# CKMD register map
Vendor: Texas Instruments
Registers are 32-bit, access per field, reset 0x0 unless marked. A register's access mark holds for its fields unless they carry their own. Offsets are as the file gives them; [hi:lo] are bit positions; 'fields as' and 'values as' point back to an identical list.

## CKMD (part 2 of 2) — Clock Controller
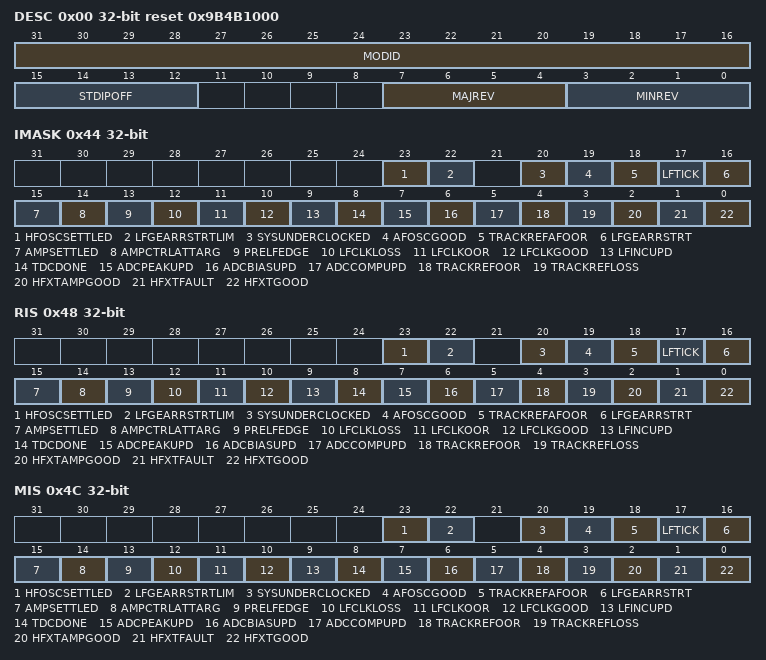
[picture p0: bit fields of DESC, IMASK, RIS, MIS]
0x00 DESC ro reset 0x9B4B1000 — IP Description
  [31:16] MODID — Module identifier
  [15:12] STDIPOFF — Standard IP MMR block offset
  [7:4] MAJREV — Major revision
  [3:0] MINREV — Minor revision
0x44 IMASK — Interrupt mask. This register selects interrupt sources which are allowed to pass from RIS to MIS when the corresponding bit-fields are set to 1.
  [23] HFOSCSETTLED rw — Indicates that HFOSC has settled, based on LOOPCFG.SETTLED_TARGET and LOOPCFG1.SETTLEIRQ
  [22] LFGEARRSTRTLIM rw — Indicates that the LFINC filter gearing mechanism has restarted more than LFINCCTL2.GEARRSTRTLIM
  [20] SYSUNDERCLOCKED rw — Indicates system frequency has been lowered. It will be set only if HFTRACKCTL.UNDERCLK is appropriately configured and HFOSC tracking loop is not running.
  [19] AFOSCGOOD rw — AFOSC good indication.
  [18] TRACKREFAFOOR rw — Out-of-range indication from the AFOSC tracking loop. Indicates that the reference clock frequency of AFOSC tracking loop is out-of-range.
  [17] LFTICK rw — 32kHz TICK to RTC and WDT. Either derived from selected LFCLK or generated from CLKULL in absence of LFCLK.
  [16] LFGEARRSTRT rw — LFINC filter gearing restart. Indicates that the LFINC filter restarted gearing. Subsequent LFINC estimates may have higher variation.
  [15] AMPSETTLED rw — HFXT Amplitude compensation - settled Indicates that the amplitude compensation FSM has reached the SETTLED or TCXOMODE state, and the controls configured in HFXTTARG or HFXTDYN are reached.
  [14] AMPCTRLATTARG rw — HFXT Amplitude compensation - controls at target Indicates that the control values configured in HFXTTARG or HFXTDYN are reached. Applies to Q1CAP, Q2CAP and IREF.
  [13] PRELFEDGE rw — Pre-LF clock edge detect. Indicates that a positive edge occured on the selected pre-LF clock CLKSEL.PRELFCLK' Can be used by software to confirm that a LF clock source is running and within the expected frequency, before selecting it as the main LF clock source.
  [12] LFCLKLOSS rw — LF clock is lost. Indicates that no LF clock edge occured for ~49us (~1.6 times nominal period). The system will automatically fall-back to generating LFTICK based on CLKULL, to avoid timing corruption. Note that this signal is NOT related to the analog LF clock-loss detector which can reset the device during STANDBY.
  [11] LFCLKOOR rw — LF clock period out-of-range. Indicates that a LF clock period was measured to be out-of-range, according to LFQUALCTL.MAXERR.
  [10] LFCLKGOOD rw — LF clock good. Indicates that the LF clock is good, according to the configuration in LFQUALCTL.
  [9] LFINCUPD rw — LFINC updated. Indicates that a new LFINC measurement value is available in LFCLKSTAT.LFINC.
  [8] TDCDONE rw — TDC done event. Indicates that the TDC measurement is done.
  [7] ADCPEAKUPD rw — HFXT-ADC PEAK measurement update event. Indicates that the HFXT-ADC PEAK measurement is done.
  [6] ADCBIASUPD rw — HFXT-ADC BIAS measurement update event. Indicates that the HFXT-ADC BIAS measurement is done.
  [5] ADCCOMPUPD rw — HFXT-ADC comparison update event. Indicates that the HFXT-ADC comparison is done.
  [4] TRACKREFOOR rw — Out-of-range indication from the tracking loop. Indicates that the selected reference clock frequency of the tracking loop is out-of-range.
  [3] TRACKREFLOSS rw — Clock loss indication from the tracking loop. Indicates that the selected reference clock of the tracking loop is lost.
  [2] HFXTAMPGOOD rw — HFXT amplitude good indication.
  [1] HFXTFAULT rw — HFXT fault indication. Indicates that HFXT did not start correctly, or its frequency is too low. HFXT will not recover from this fault and has to be restarted. This is only a one-time check at HFXT startup.
  [0] HFXTGOOD rw — HFXT good indication. Indicates that HFXT started correctly. The frequency is not necessarily good enough for radio operation. This is only a one-time check at HFXT startup.
0x48 RIS ro — Raw interrupt flag register
  [23] HFOSCSETTLED — Indicates that HFOSC has settled, based on LOOPCFG.SETTLED_TARGET and LOOPCFG1.SETTLEIRQ
  [22] LFGEARRSTRTLIM — Indicates that the LFINC filter gearing mechanism has restarted more than LFINCCTL2.GEARRSTRTLIM
  [20] SYSUNDERCLOCKED — Indicates system frequency has been lowered. It will be set only if HFTRACKCTL.UNDERCLK is appropriately configured and HFOSC tracking loop is not running.
  [19] AFOSCGOOD — AFOSC good indication.
  [18] TRACKREFAFOOR — Out-of-range indication from the AFOSC tracking loop. Indicates that the reference clock frequency of AFOSC tracking loop is out-of-range.
  [17] LFTICK — 32kHz TICK to RTC and WDT. Either derived from selected LFCLK or generated from CLKULL in absence of LFCLK.
  [16] LFGEARRSTRT — LFINC filter gearing restart. Indicates that the LFINC filter restarted gearing. Subsequent LFINC estimates may have higher variation.
  [15] AMPSETTLED — HFXT Amplitude compensation - settled Indicates that the amplitude compensation FSM has reached the SETTLED or TCXOMODE state, and the controls configured in HFXTTARG or HFXTDYN are reached.
  [14] AMPCTRLATTARG — HFXT Amplitude compensation - controls at target Indicates that the control values configured in HFXTTARG or HFXTDYN are reached. Applies to Q1CAP, Q2CAP and IREF.
  [13] PRELFEDGE — Pre-LF clock edge detect. Indicates that a positive edge occured on the selected pre-LF clock CLKSEL.PRELFCLK' Can be used by software to confirm that a LF clock source is running and within the expected frequency, before selecting it as the main LF clock source.
  [12] LFCLKLOSS — LF clock is lost. Indicates that no LF clock edge occured for ~49us (~1.6 times nominal period). The system will automatically fall-back to generating LFTICK based on CLKULL, to avoid timing corruption. Note that this signal is NOT related to the analog LF clock-loss detector which can reset the device during STANDBY.
  [11] LFCLKOOR — LF clock period out-of-range. Indicates that a LF clock period was measured to be out-of-range, according to LFQUALCTL.MAXERR.
  [10] LFCLKGOOD — LF clock good. Indicates that the LF clock is good, according to the configuration in LFQUALCTL.
  [9] LFINCUPD — LFINC updated. Indicates that a new LFINC measurement value is available in LFCLKSTAT.LFINC.
  [8] TDCDONE — TDC done event. Indicates that the TDC measurement is done.
  [7] ADCPEAKUPD — HFXT-ADC PEAK measurement update event. Indicates that the HFXT-ADC PEAK measurement is done.
  [6] ADCBIASUPD — HFXT-ADC BIAS measurement update event. Indicates that the HFXT-ADC BIAS measurement is done.
  [5] ADCCOMPUPD — HFXT-ADC comparison update event. Indicates that the HFXT-ADC comparison is done.
  [4] TRACKREFOOR — Out-of-range indication from the tracking loop. Indicates that the selected reference clock frequency of the tracking loop is out-of-range.
  [3] TRACKREFLOSS — Clock loss indication from the tracking loop. Indicates that the selected reference clock of the tracking loop is lost.
  [2] HFXTAMPGOOD — HFXT amplitude good indication.
  [1] HFXTFAULT — HFXT fault indication. Indicates that HFXT did not start correctly, or its frequency is too low. HFXT will not recover from this fault and has to be restarted. This is only a one-time check at HFXT startup.
  [0] HFXTGOOD — HFXT good indication. Indicates that HFXT started correctly. The frequency is not necessarily good enough for radio operation. This is only a one-time check at HFXT startup.
0x4C MIS ro — Masked interrupt flag register
  fields as RIS
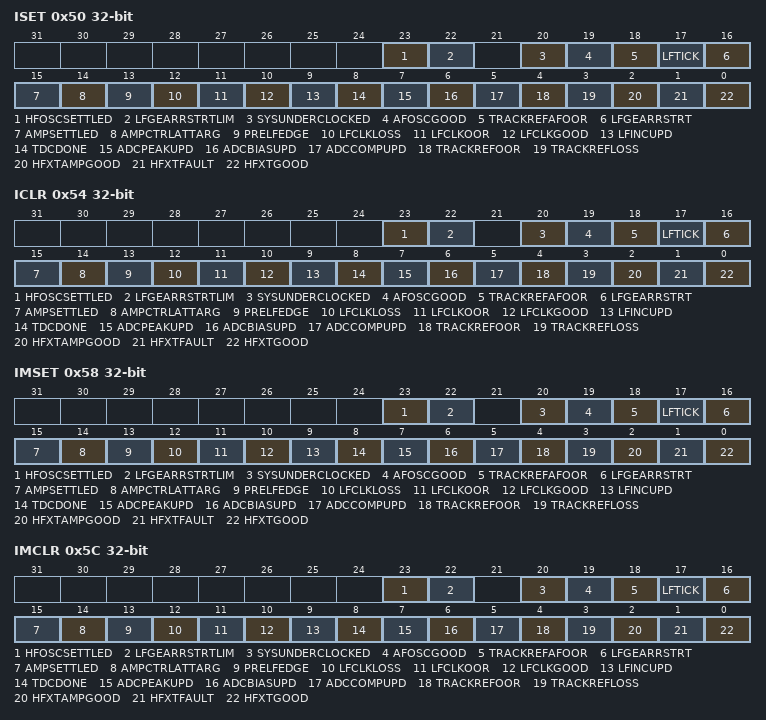
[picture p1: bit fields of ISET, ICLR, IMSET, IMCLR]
0x50 ISET — Interrupt flag set register
  [23] HFOSCSETTLED wo — Indicates that HFOSC has settled, based on LOOPCFG.SETTLED_TARGET and LOOPCFG1.SETTLEIRQ
  [22] LFGEARRSTRTLIM wo — Indicates that the LFINC filter gearing mechanism has restarted more than LFINCCTL2.GEARRSTRTLIM
  [20] SYSUNDERCLOCKED wo — Indicates system frequency has been lowered. It will be set only if HFTRACKCTL.UNDERCLK is appropriately configured and HFOSC tracking loop is not running.
  [19] AFOSCGOOD wo — AFOSC good indication.
  [18] TRACKREFAFOOR wo — Out-of-range indication from the AFOSC tracking loop. Indicates that the reference clock frequency of AFOSC tracking loop is out-of-range.
  [17] LFTICK wo — 32kHz TICK to RTC and WDT. Either derived from selected LFCLK or generated from CLKULL in absence of LFCLK.
  [16] LFGEARRSTRT wo — LFINC filter gearing restart. Indicates that the LFINC filter restarted gearing. Subsequent LFINC estimates may have higher variation.
  [15] AMPSETTLED wo — HFXT Amplitude compensation - settled Indicates that the amplitude compensation FSM has reached the SETTLED or TCXOMODE state, and the controls configured in HFXTTARG or HFXTDYN are reached.
  [14] AMPCTRLATTARG wo — HFXT Amplitude compensation - controls at target Indicates that the control values configured in HFXTTARG or HFXTDYN are reached. Applies to Q1CAP, Q2CAP and IREF.
  [13] PRELFEDGE wo — Pre-LF clock edge detect. Indicates that a positive edge occured on the selected pre-LF clock CLKSEL.PRELFCLK' Can be used by software to confirm that a LF clock source is running and within the expected frequency, before selecting it as the main LF clock source.
  [12] LFCLKLOSS wo — LF clock is lost. Indicates that no LF clock edge occured for ~49us (~1.6 times nominal period). The system will automatically fall-back to generating LFTICK based on CLKULL, to avoid timing corruption. Note that this signal is NOT related to the analog LF clock-loss detector which can reset the device during STANDBY.
  [11] LFCLKOOR wo — LF clock period out-of-range. Indicates that a LF clock period was measured to be out-of-range, according to LFQUALCTL.MAXERR.
  [10] LFCLKGOOD wo — LF clock good. Indicates that the LF clock is good, according to the configuration in LFQUALCTL.
  [9] LFINCUPD wo — LFINC updated. Indicates that a new LFINC measurement value is available in LFCLKSTAT.LFINC.
  [8] TDCDONE wo — TDC done event. Indicates that the TDC measurement is done.
  [7] ADCPEAKUPD wo — HFXT-ADC PEAK measurement update event. Indicates that the HFXT-ADC PEAK measurement is done.
  [6] ADCBIASUPD wo — HFXT-ADC BIAS measurement update event. Indicates that the HFXT-ADC BIAS measurement is done.
  [5] ADCCOMPUPD wo — HFXT-ADC comparison update event. Indicates that the HFXT-ADC comparison is done.
  [4] TRACKREFOOR wo — Out-of-range indication from the tracking loop. Indicates that the selected reference clock frequency of the tracking loop is out-of-range.
  [3] TRACKREFLOSS wo — Clock loss indication from the tracking loop. Indicates that the selected reference clock of the tracking loop is lost.
  [2] HFXTAMPGOOD wo — HFXT amplitude good indication.
  [1] HFXTFAULT wo — HFXT fault indication. Indicates that HFXT did not start correctly, or its frequency is too low. HFXT will not recover from this fault and has to be restarted. This is only a one-time check at HFXT startup.
  [0] HFXTGOOD wo — HFXT good indication. Indicates that HFXT started correctly. The frequency is not necessarily good enough for radio operation. This is only a one-time check at HFXT startup.
0x54 ICLR — Interrupt flag clear register
  fields as ISET
0x58 IMSET — Interrupt mask set register
  fields as ISET
0x5C IMCLR — Interrupt mask clear register. Writing a 1 to a bit in this register will clear the corresponding IMASK bit.
  fields as ISET
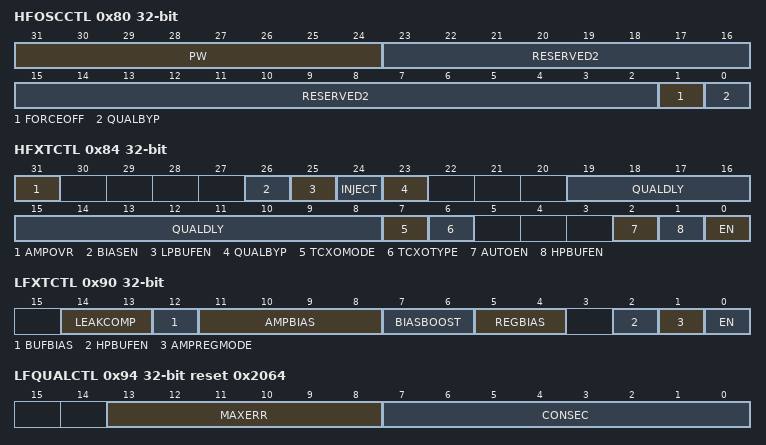
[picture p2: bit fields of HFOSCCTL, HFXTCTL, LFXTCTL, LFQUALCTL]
0x80 HFOSCCTL — Internal. Only to be used through TI provided API.
  [31:24] PW wo — Internal. Only to be used through TI provided API.
  [23:2] RESERVED2 ro — Internal. Only to be used through TI provided API.
  [1] FORCEOFF rw — Internal. Only to be used through TI provided API.
  [0] QUALBYP rw — Internal. Only to be used through TI provided API.
0x84 HFXTCTL — High frequency crystal control
  [31] AMPOVR rw — Internal. Only to be used through TI provided API.
  [26] BIASEN rw — Internal. Only to be used through TI provided API.
  [25] LPBUFEN rw — Internal. Only to be used through TI provided API.
  [24] INJECT rw — Internal. Only to be used through TI provided API.
  [23] QUALBYP rw — Internal. Only to be used through TI provided API.
  [19:8] QUALDLY rw — Skip potentially unstable clock cycles after enabling HFXT. Number of cycles skipped is 8*QUALDLY.
  [7] TCXOMODE rw — Temperature compensated crystal oscillator mode. Set this bit if a TXCO is connected.
  [6] TCXOTYPE rw — Type of temperature compensated crystal used. Only has effect if TCXOMODE is set.
    1=CMOS (Use with CMOS TCXO); 0=CLIPPEDSINE (Use with clipped-sine TCXO)
  [2] AUTOEN rw — Internal. Only to be used through TI provided API.
  [1] HPBUFEN rw — High performance clock buffer enable. This bit controls the clock output for the RF PLL. It is required for radio operation.
  [0] EN rw — Internal. Only to be used through TI provided API.
0x8C LFOSCCTL — Low frequency oscillator control
  [0] EN rw — LFOSC enable
0x90 LFXTCTL — Low frequency crystal control
  [14:13] LEAKCOMP rw — Leakage compensation control
    3=OFF (No leakage compensation); 1=HALF (Half leakage compensation); 0=FULL (Full leakage compensation)
  [12] BUFBIAS rw — Control the BIAS current of the input amp in LP buffer
    1=MAX (Maximum bias current: 50nA); 0=MIN (Minimum bias current: 25nA)
  [11:8] AMPBIAS rw — Adjust current mirror ratio into oscillator core. This value is depending on crystal and is set by FW. This field uses a 2's complement encoding.
  [7:6] BIASBOOST rw — Boost oscillator amplitude This value depends on the crystal and needs to be configured by Firmware.
  [5:4] REGBIAS rw — Regulation loop bias resistor value This value depends on the crystal and needs to be configured by Firmware.
  [2] HPBUFEN rw — Control the buffer used. In normal operation, low-power buffer is used in all device modes. The high-performance buffer is only used for test purposes.
  [1] AMPREGMODE rw — Amplitude regulation mode
    1=LOOPDIS (Amplitude control loop disabled); 0=LOOPEN (Amplitude control loop enabled)
  [0] EN rw — LFXT enable
0x94 LFQUALCTL reset 0x2064 — Low frequency clock qualification control
  [13:8] MAXERR rw — Maximum LFCLK period error. Value given in microseconds, 3 integer bits + 3 fractional bits.
  [7:0] CONSEC rw — Number of consecutive times the LFCLK period error has to be smaller than MAXERR to be considered "good". Setting this value to 0 will bypass clock qualification, and the "good" indicator will always be 1.
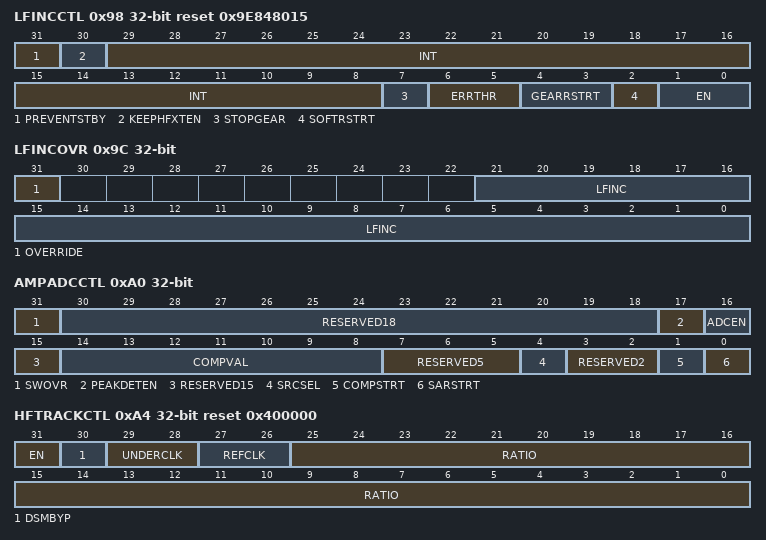
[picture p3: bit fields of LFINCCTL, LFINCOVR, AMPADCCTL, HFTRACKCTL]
0x98 LFINCCTL rw reset 0x9E848015 — Low frequency time increment control
  [31] PREVENTSTBY — Controls if the LFINC filter prevents STANBY entry until settled.
    1=ON (Enable. Prevent STANDBY entry.); 0=OFF (Disable. Do not prevent STANDBY entry.)
  [30] KEEPHFXTEN — Keeps the HFXT enabled till the LFINC filter settles
    1=EN (Enable. Keep HFXT enabled.); 0=DIS (Disable. Do not keep HFXT enabled.)
  [29:8] INT — Integral part of the LFINC filter. This value is updated by Hardware to reflect the current state of the filter. It can also be written to change the current state.
  [7] STOPGEAR — Controls the final gear of the LFINC filter.
    1=HIGH (The LF filter is considered settled when LFCLKSTAT2.MAINGEAR reads 8 and LFCLKSTAT2.SUBGEAR reads 7. That means the LF filter will take 71 LF periods to settle provided the gear does not restarts.); 0=LOW (The LF filter is considered settled when LFCLKSTAT2.MAINGEAR reads 9 and LFCLKSTAT2.SUBGEAR reads 7. That means the LF filter will take 79 LF periods to settle provided the gear does not restarts.)
  [6:5] ERRTHR — Controls the threshold for gearing restart of the LFINC filter. Only effective if GEARRSTRT is not ONETHR or TWOTHR.
    3=SMALL (Restart gearing on small error. Potentially more false restarts, faster response on small frequency shifts.); 2=MIDSMALL (Middle value towards SMALL.); 1=MIDLARGE (Middle value towards LARGE.); 0=LARGE (Restart gearing on large error. Fewer false restarts, slower response on small frequency shifts.)
  [4:3] GEARRSTRT — Controls gearing restart of the LFINC filter.
    2=TWOTHR (Restart gearing when the error accumulator crosses the threshold twice in a row.); 1=ONETHR (Restart gearing when the error accumulator crosses the threshold once.); 0=NEVER (Never restart gearing. Very stable filter value, but very slow response on frequency changes.)
  [2] SOFTRSTRT — Use a higher gear after re-enabling / wakeup. The filter will require 16-24 LFCLK periods to settle (depending on STOPGEAR), but may respond faster to frequency changes during STANDBY.
    1=ON (Use soft gearing restarts); 0=OFF (Don't use soft gearing restarts)
  [1:0] EN — Enable LFINC filter. Programming with a value of 0x3 will disable the LFINC filter
    2=AUTO (Enable based on HFOS getting settled. HFOSC gets settled after the tracking loop has updated equal to or more than LOOPCFG.SETTLED_TARGET times.); 1=EN (ENABLED); 0=DIS (DISABLED)
0x9C LFINCOVR — Low frequency time increment override control
  [31] OVERRIDE rw — Override LF increment Use the value provided in LFINC instead of the value calculated by Hardware.
  [21:0] LFINC rw — LF increment value This value is used when OVERRIDE is set to 1. Otherwise the value is calculated automatically. The current LFINC value can be read from [CKM.LFCLKSTAT.LFINC].
0xA0 AMPADCCTL — Internal. Only to be used through TI provided API.
  [31] SWOVR rw — Internal. Only to be used through TI provided API.
  [30:18] RESERVED18 ro — Internal. Only to be used through TI provided API.
  [17] PEAKDETEN rw — Internal. Only to be used through TI provided API.
    1=ENABLE (Internal. Only to be used through TI provided API.); 0=DISABLE (Internal. Only to be used through TI provided API.)
  [16] ADCEN rw — Internal. Only to be used through TI provided API.
    values as PEAKDETEN
  [15] RESERVED15 ro — Internal. Only to be used through TI provided API.
  [14:8] COMPVAL rw — Internal. Only to be used through TI provided API.
  [7:5] RESERVED5 ro — Internal. Only to be used through TI provided API.
  [4] SRCSEL rw — Internal. Only to be used through TI provided API.
    1=PEAK (Internal. Only to be used through TI provided API.); 0=BIAS (Internal. Only to be used through TI provided API.)
  [3:2] RESERVED2 ro — Internal. Only to be used through TI provided API.
  [1] COMPSTRT rw — Internal. Only to be used through TI provided API.
  [0] SARSTRT rw — Internal. Only to be used through TI provided API.
0xA4 HFTRACKCTL rw reset 0x400000 — High frequency tracking loop control
  [31] EN — Enable tracking loop.
  [30] DSMBYP — Bypass Delta-Sigma-Modulation of fine trim.
  [29:28] UNDERCLK — When the HFOSC tracking loop is not running, this bitfield can be used to set the condition to automatically lower the HFOSC frequency. This will prevent frequency drift that may lead to SOC instability.
    3=BOTH (Temperature event from Batmon or Timer event); 2=BATMON (Temperature event from Batmon); 1=TIMER (Timer event); 0=DIS (Disable)
  [27:26] REFCLK — Select the reference clock for the tracking loop. Change only while the tracking loop is disabled.
    2=GPI (Select GPI as reference clock.); 1=LRF (Select LRF reference clock.); 0=HFXT (Select HFXT as reference clock.)
  [25:0] RATIO — Reference clock ratio. Ratio format is 2b.24b RATIO = 24MHz / (2*reference-frequency) * 2^24 Commonly used reference clock frequencies are provided as enumerations.
    0x3000000=REF4M (Use for 4MHz reference clock); 0x1800000=REF8M (Use for 8MHz Reference clock); 0x400000=REF48M (Use for 48MHz reference clock)
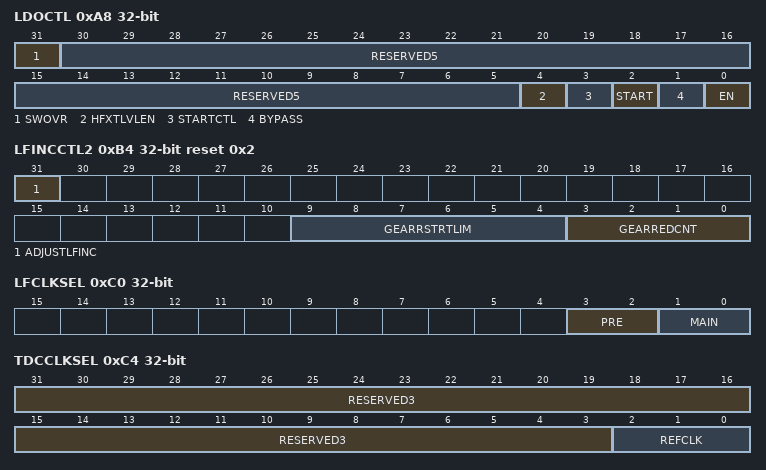
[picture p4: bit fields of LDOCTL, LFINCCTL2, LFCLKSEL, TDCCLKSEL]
0xA8 LDOCTL — Internal. Only to be used through TI provided API.
  [31] SWOVR rw — Internal. Only to be used through TI provided API.
  [30:5] RESERVED5 ro — Internal. Only to be used through TI provided API.
  [4] HFXTLVLEN rw — Internal. Only to be used through TI provided API.
  [3] STARTCTL rw — Internal. Only to be used through TI provided API.
  [2] START rw — Internal. Only to be used through TI provided API.
  [1] BYPASS rw — Internal. Only to be used through TI provided API.
  [0] EN rw — Internal. Only to be used through TI provided API.
0xAC NABIASCTL — Nanoamp-bias control
  [0] EN rw — Enable nanoamp-bias
0xB0 LFMONCTL — Low-frequency clock-monitor control
  [0] EN rw — Enable LFMONITOR. Enable only after a LF clock source has been selected, enabled and is stable. If LFMONITOR detects a clock loss, the system will be reset.
0xB4 LFINCCTL2 reset 0x2 — Low frequency time increment control-2
  [31] ADJUSTLFINC rw — Adjusts LFINC while transitioning from fake to real LF clock if necessary. For the adjustment to happen, tracking loop must be running.
  [9:4] GEARRSTRTLIM rw — Specifies the number of times gear could be restarted before raising an interrupt. It has no impact on the number of times gear can be reduced. A value of 0 indicates that the interrupt mechanism is disabled
  [3:0] GEARREDCNT rw — Specifies the number by which gear should be reduced post standby exit
0xC0 LFCLKSEL — Low frequency clock selection
  [3:2] PRE rw — Select low frequency clock source for the PRELFCLK interrupt. Can be used by Software to confirm that the clock is running and it's frequency is good, before selecting it in MAIN.
    3=EXTLF (External LF clock through GPI.); 2=LFXT (Low frequency crystal oscillator); 1=LFOSC (Low frequency on-chip oscillator); 0=NONE (No clock. Output will be tied low.)
  [1:0] MAIN rw — Select the main low frequency clock source. If running, this clock will be used to generate LFTICK and as CLKULL during STANDBY. If not running, LFTICK will be generated from HFOSC and STANDBY entry will be prevented.
    3=EXTLF (External LF clock through GPI.); 2=LFXT (Low frequency crystal oscillator); 1=LFOSC (Low frequency on-chip oscillator); 0=FAKE (No LF clock selected. LFTICK will be generated from HFOSC, STANDBY entry will be prevented.)
0xC4 TDCCLKSEL — Internal. Only to be used through TI provided API.
  [31:3] RESERVED3 ro — Internal. Only to be used through TI provided API.
  [2:0] REFCLK rw — Internal. Only to be used through TI provided API.
    5=HFXT (Internal. Only to be used through TI provided API.); 4=AFOSC (Internal. Only to be used through TI provided API.); 3=GPI (Internal. Only to be used through TI provided API.); 2=CLKULL (Internal. Only to be used through TI provided API.); 1=CLKSVT (Internal. Only to be used through TI provided API.); 0=NONE (Internal. Only to be used through TI provided API.)
0xC8 ADCCLKSEL — ADC clock selection
  [1:0] SRC rw — Select ADC clock source Change only while ADC is disabled!
    1=HFXT (48MHz HFXT); 0=CLKSVT (48MHz CLKSVT)
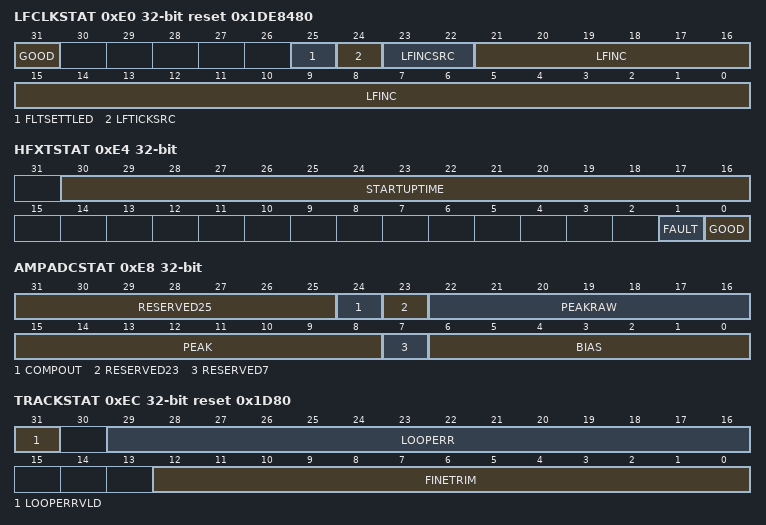
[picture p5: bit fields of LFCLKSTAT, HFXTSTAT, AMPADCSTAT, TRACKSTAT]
0xE0 LFCLKSTAT ro reset 0x1DE8480 — Low-frequency clock status
  [31] GOOD — Low frequency clock good Note: This is only a coarse frequency check based on LFQUALCTL. The clock may not be accurate enough for timing purposes.
  [25] FLTSETTLED — LFINC filter is running and settled.
  [24] LFTICKSRC — Source of LFTICK.
    1=FAKE (LFTICK generated from CLKULL (LFCLK not available)); 0=LFCLK (LFTICK generated from the selected LFCLK)
  [23:22] LFINCSRC — Source of LFINC used by the RTC. This value depends on LFINCOVR.OVERRIDE, LF clock availability, HF tracking loop status and the device state (ACTIVE/STANDBY).
    3=FAKE (Using FAKE LFTICKs with corresponding LFINC value.); 2=OVERRIDE (Using override value from LFINCOVR.LFINC); 1=AVG (Using filtered / average value. This value is updated by hardware and can be read and updated in LFINCCTL.INT.); 0=MEAS (Using measured value. This value is updated by hardware and can be read from LFINC.)
  [21:0] LFINC — Measured value of LFINC. Given in microseconds with 16 fractional bits. This value is calculated by Hardware. It is the LFCLK period according to CLKULL cycles.
0xE4 HFXTSTAT ro — HFXT status information
  [30:16] STARTUPTIME — HFXT startup time Can be used by software to plan starting HFXT ahead in time. Measured whenever HFXT is enabled in CLKULL periods (24MHz), from HFXTCTL.EN until the clock is good for radio operation (amplitude compensation is settled).
  [1] FAULT — HFXT clock fault Indicates a lower than expected HFXT frequency. HFXT will not recover from this fault, disabling and re-enabling HFXT is required.
  [0] GOOD — HFXT clock available. The frequency is not necessarily good enough for radio operation.
0xE8 AMPADCSTAT ro — Internal. Only to be used through TI provided API.
  [31:25] RESERVED25 — Internal. Only to be used through TI provided API.
  [24] COMPOUT — Internal. Only to be used through TI provided API.
  [23] RESERVED23 — Internal. Only to be used through TI provided API.
  [22:16] PEAKRAW — Internal. Only to be used through TI provided API.
  [15:8] PEAK — Internal. Only to be used through TI provided API.
  [7] RESERVED7 — Internal. Only to be used through TI provided API.
  [6:0] BIAS — Internal. Only to be used through TI provided API.
0xEC TRACKSTAT ro reset 0x1D80 — HF tracking loop status information
  [31] LOOPERRVLD — Current HFOSC tracking error valid This bit is one if the tracking loop is running and the error value is valid.
  [29:16] LOOPERR — Current HFOSC tracking error This field uses the internal fractional representation (sign, 9 integer bits, 4 fractional bits).
  [12:0] FINETRIM — Current HFOSC Fine-trim value This field uses the internal fractional representation (sign, 5 integer bits, 7 fractional bits). The actual trim value applied to the oscillator is delta-sigma modulated 6 bits non-signed (inverted sign bit + integer bits).
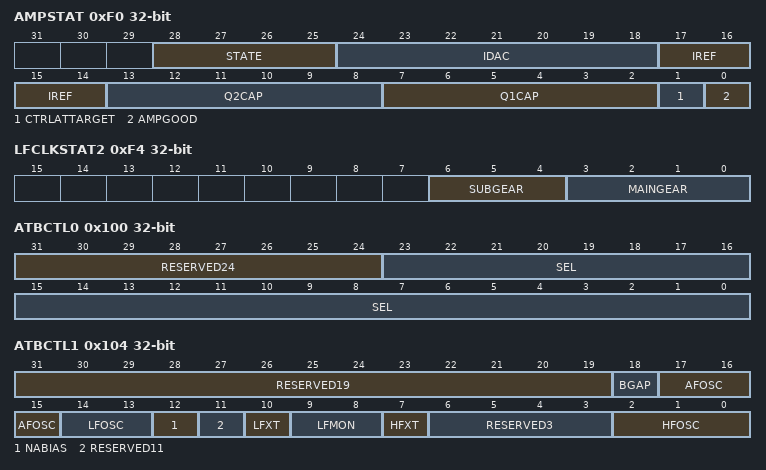
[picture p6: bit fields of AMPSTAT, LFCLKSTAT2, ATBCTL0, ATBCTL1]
0xF0 AMPSTAT ro — HFXT Amplitude Compensation Status
  [28:25] STATE — Current AMPCOMP FSM state.
    15=SETTLED (Settled state); 14=UPDATEUP (Amplitude up correction); 12=TXCOMODE (TCXO settled state); 10=SHUTDN0 (First shutdown state); 7=INJWAIT (Post injection settle wait); 6=UPDATEDN (Amplitude down correction); 5=RAMP0 (Initial amplitude ramping with HFXTINIT values); 4=RAMP1 (Transition to HFXTTARG values); 3=INJECT (Injecting HFOSC for fast startup); 2=SHUTDN1 (Second shutdown state); 1=LDOSTART (Starting LDO); 0=IDLE (FSM in idle state)
  [24:18] IDAC — Current IDAC control value.
  [17:14] IREF — Current IREF control value.
  [13:8] Q2CAP — Current Q2CAP control value.
  [7:2] Q1CAP — Current Q1CAP control value.
  [1] CTRLATTARGET — HFXT control values match target values. This applies to IREF, Q1CAP, Q2CAP values.
  [0] AMPGOOD — HFXT amplitude good
0xF4 LFCLKSTAT2 ro — Low-frequency clock status-2
  [6:4] SUBGEAR — The value of sub gear in LF filter. It counts from 0 to 7.
  [3:0] MAINGEAR — The value of main gear in LF filter. The main gear increments when the sub gear crosses 7.
0x100 ATBCTL0 — Internal. Only to be used through TI provided API.
  [31:24] RESERVED24 ro — Internal. Only to be used through TI provided API.
  [23:0] SEL rw — Internal. Only to be used through TI provided API.
    0x90000=AFOSCTESTCLK (Internal. Only to be used through TI provided API.); 0x70000=LFXTTESTCLK (Internal. Only to be used through TI provided API.); 0x50000=LFOSCTESTCLK (Internal. Only to be used through TI provided API.); 0x30000=HFXTTESTCLK (Internal. Only to be used through TI provided API.); 0x10000=HFOSCTESTCLK (Internal. Only to be used through TI provided API.); 0x4000=AFOSCOUT (Internal. Only to be used through TI provided API.); 0x1000=LFMONVTEST (Internal. Only to be used through TI provided API.); 0x100=HFOSCOUT (Internal. Only to be used through TI provided API.); 128=NABIASITEST (Internal. Only to be used through TI provided API.); 64=ADCDACOUT (Internal. Only to be used through TI provided API.); 32=ADCCOMPIN (Internal. Only to be used through TI provided API.); 16=ADCCOMPOUT (Internal. Only to be used through TI provided API.); 8=LFXTANA (Internal. Only to be used through TI provided API.); 2=VDDCKM (Internal. Only to be used through TI provided API.); 1=HFXTANA (Internal. Only to be used through TI provided API.); 0=OFF (Internal. Only to be used through TI provided API.)
0x104 ATBCTL1 — Internal. Only to be used through TI provided API.
  [31:19] RESERVED19 ro — Internal. Only to be used through TI provided API.
  [18] BGAP rw — Internal. Only to be used through TI provided API.
  [17:15] AFOSC rw — Internal. Only to be used through TI provided API.
  [14:13] LFOSC rw — Internal. Only to be used through TI provided API.
    3=BOTH (Internal. Only to be used through TI provided API.); 2=VDDLOCAL (Internal. Only to be used through TI provided API.); 1=TESTCLK (Internal. Only to be used through TI provided API.); 0=OFF (Internal. Only to be used through TI provided API.)
  [12] NABIAS rw — Internal. Only to be used through TI provided API.
  [11] RESERVED11 ro — Internal. Only to be used through TI provided API.
  [10] LFXT rw — Internal. Only to be used through TI provided API.
    1=TESTCLK (Internal. Only to be used through TI provided API.); 0=OFF (Internal. Only to be used through TI provided API.)
  [9:8] LFMON rw — Internal. Only to be used through TI provided API.
    2=TEST2 (Internal. Only to be used through TI provided API.); 1=TEST1 (Internal. Only to be used through TI provided API.); 0=OFF (Internal. Only to be used through TI provided API.)
  [7] HFXT rw — Internal. Only to be used through TI provided API.
  [6:3] RESERVED3 ro — Internal. Only to be used through TI provided API.
  [2:0] HFOSC rw — Internal. Only to be used through TI provided API.
